# USBFS0_1.0 register map
Vendor: Texas Instruments
Peripheral module from a debugger description file (folder mspm0g511x).
Registers are 8-bit, read-write, no defined reset value unless marked. A register's access mark holds for its fields unless they carry their own. Offsets are as the file gives them; lines under a group give offsets from that group; [hi:lo] are bit positions; {n}, {i} and the like mark numbered series; 'fields as' and 'values as' point back to an identical list; <NAME> marks a mode.

## USBFS0 (part 1 of 2)
0x800 USBFS0_GPRCM group
  0x00 USBFS0_PWREN 32-bit — Power enable
    [0] ENABLE — Enable the power
      0=DISABLE (Disable Power); 1=ENABLE (Enable Power)
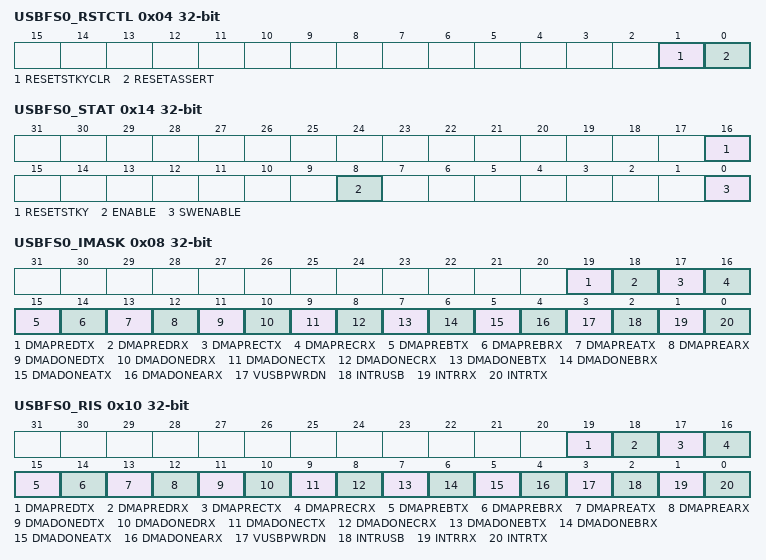
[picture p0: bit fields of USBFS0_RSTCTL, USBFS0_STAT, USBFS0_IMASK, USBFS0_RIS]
  0x04 USBFS0_RSTCTL 32-bit — Reset Control
    [1] RESETSTKYCLR — Clear the RESETSTKY bit in the STAT register
      0=NOP (Writing 0 has no effect); 1=CLR (Clear reset sticky bit)
    [0] RESETASSERT — Assert reset to the peripheral
      0=NOP (Writing 0 has no effect); 1=ASSERT (Assert reset)
  0x14 USBFS0_STAT 32-bit access per field — Status Register
    [16] RESETSTKY ro — This bit indicates, if the peripheral was reset, since this bit was cleared by RESETSTKYCLR in the RSTCTL register
      0=NORES (The peripheral has not been reset since this bit was last cleared by RESETSTKYCLR in the RSTCTL register); 1=RESET (The peripheral was reset since the last bit clear)
    [8] ENABLE rw — Peripheral enable status
      0=OFF (Peripheral is disabled); 1=ON (Peripheral is enabled)
    [0] SWENABLE ro — Software enable status. Shows if enabled via PWREN.ENABLE bit
      0=DISABLED (Not enabled via PWREN.ENABLE bit); 1=ENABLED (Enabled via PWREN.ENABLE bit)
0x1020 USBFS0_CPU_INT group
  0x00 USBFS0_IIDX 32-bit ro — Interrupt index
    [7:0] STAT — Interrupt index status
      0=NO_INTR (No bit is set means there is no pending interrupt request); 1=INTRTX (Endpoint 0 and the TX Endpoints interrupt); 2=INTRRX (RX Endpoints interrupt); 3=INTRUSB (USB Interrupts); 4=VUSBPWRDN (VUSB power down); 5=DMADONEARX (DMA-Done interrupt for Trigger USB-A-RX); 6=DMADONEATX (DMA-Done interrupt for Trigger USB-A-TX); 7=DMADONEBRX (DMA-Done interrupt for Trigger USB-B-RX); 8=DMADONEBTX (DMA-Done interrupt for Trigger USB-B-TX); 9=DMADONECRX (DMA-Done interrupt for Trigger USB-C-RX); 10=DMADONECTX (DMA-Done interrupt for Trigger USB-C-TX); 11=DMADONEDRX (DMA-Done interrupt for Trigger USB-D-RX); 12=DMADONEDTX (DMA-Done interrupt for Trigger USB-D-TX); 13=DMAPREARX (DMA-Pre interrupt for Trigger USB-A-RX); 14=DMAPREATX (DMA-Pre interrupt for Trigger USB-A-TX); 15=DMAPREBRX (DMA-Pre interrupt for Trigger USB-B-RX); 16=DMAPREBTX (DMA-Pre interrupt for Trigger USB-B-TX); 17=DMAPRECRX (DMA-Pre interrupt for Trigger USB-C-RX); 18=DMAPRECTX (DMA-Pre interrupt for Trigger USB-C-TX); 19=DMAPREDRX (DMA-Pre interrupt for Trigger USB-D-RX); 20=DMAPREDTX (DMA-Pre interrupt for Trigger USB-D-TX)
  0x08 USBFS0_IMASK 32-bit — Interrupt mask
    [all] fields
      0=CLR (Interrupt Disabled.); 1=SET (Interrupt Enabled.)
    [19] DMAPREDTX — DMA-Pre interrupt for Trigger USB-D-TX
    [18] DMAPREDRX — DMA-Pre interrupt for Trigger USB-D-RX
    [17] DMAPRECTX — DMA-Pre interrupt for Trigger USB-C-TX
    [16] DMAPRECRX — DMA-Pre interrupt for Trigger USB-C-RX
    [15] DMAPREBTX — DMA-Pre interrupt for Trigger USB-B-TX
    [14] DMAPREBRX — DMA-Pre interrupt for Trigger USB-B-RX
    [13] DMAPREATX — DMA-Pre interrupt for Trigger USB-A-TX
    [12] DMAPREARX — DMA-Pre interrupt for Trigger USB-A-RX
    [11] DMADONEDTX — DMA-Done interrupt for Trigger USB-D-TX
    [10] DMADONEDRX — DMA-Done interrupt for Trigger USB-D-RX
    [9] DMADONECTX — DMA-Done interrupt for Trigger USB-C-TX
    [8] DMADONECRX — DMA-Done interrupt for Trigger USB-C-RX
    [7] DMADONEBTX — DMA-Done interrupt for Trigger USB-B-TX
    [6] DMADONEBRX — DMA-Done interrupt for Trigger USB-B-RX
    [5] DMADONEATX — DMA-Done interrupt for Trigger USB-A-TX
    [4] DMADONEARX — DMA-Done interrupt for Trigger USB-A-RX
    [3] VUSBPWRDN — VUSB Power Down
    [2] INTRUSB — USB Interrupts
    [1] INTRRX — RX Endpoints interrupt
    [0] INTRTX — Endpoint 0 and the TX Endpoints interrupt
  0x10 USBFS0_RIS 32-bit — Raw interrupt status
    [all] fields
      0=CLR (Interrupt did not occur); 1=SET (Interrupt occured)
    [19] DMAPREDTX — DMA-Pre interrupt for Trigger USB-D-TX
    [18] DMAPREDRX — DMA-Pre interrupt for Trigger USB-D-RX
    [17] DMAPRECTX — DMA-Pre interrupt for Trigger USB-C-TX
    [16] DMAPRECRX — DMA-Pre interrupt for Trigger USB-C-RX
    [15] DMAPREBTX — DMA-Pre interrupt for Trigger USB-B-TX
    [14] DMAPREBRX — DMA-Pre interrupt for Trigger USB-B-RX
    [13] DMAPREATX — DMA-Pre interrupt for Trigger USB-A-TX
    [12] DMAPREARX — DMA-Pre interrupt for Trigger USB-A-RX
    [11] DMADONEDTX — DMA-Done interrupt for Trigger USB-D-TX
    [10] DMADONEDRX — DMA-Done interrupt for Trigger USB-D-RX
    [9] DMADONECTX — DMA-Done interrupt for Trigger USB-C-TX
    [8] DMADONECRX — DMA-Done interrupt for Trigger USB-C-RX
    [7] DMADONEBTX — DMA-Done interrupt for Trigger USB-B-TX
    [6] DMADONEBRX — DMA-Done interrupt for Trigger USB-B-RX
    [5] DMADONEATX — DMA-Done interrupt for Trigger USB-A-TX
    [4] DMADONEARX — DMA-Done interrupt for Trigger USB-A-RX
    [3] VUSBPWRDN — VUSB Power Down
    [2] INTRUSB — USB Interrupts
    [1] INTRRX — RX Endpoints interrupt
    [0] INTRTX — Endpoint 0 and the TX Endpoints interrupt
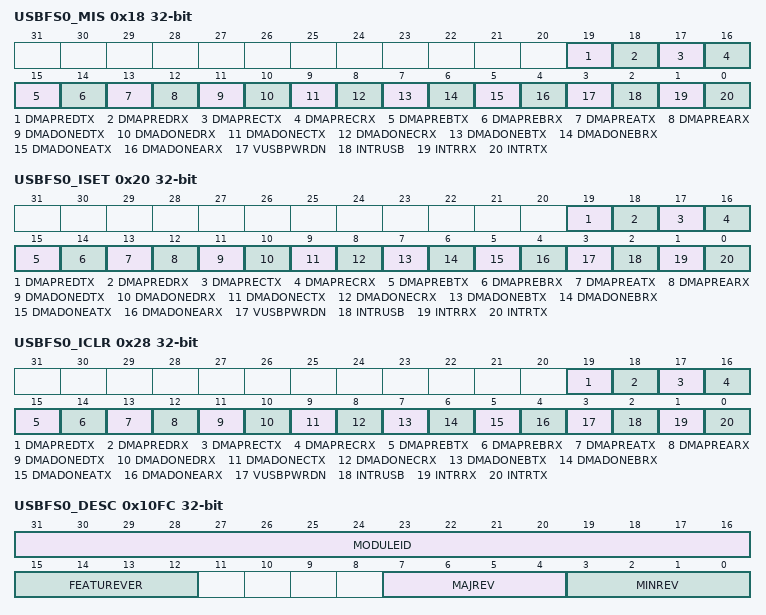
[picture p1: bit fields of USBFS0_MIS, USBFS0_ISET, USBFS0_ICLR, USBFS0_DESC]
  0x18 USBFS0_MIS 32-bit — Masked interrupt status
    fields as USBFS0_CPU_INT.USBFS0_RIS
  0x20 USBFS0_ISET 32-bit — Interrupt set
    [all] fields
      0=NO_EFFECT (Writing 0 has No Effect); 1=SET (Write 1 to set the interrupt)
    [19] DMAPREDTX — DMA-Pre interrupt for Trigger USB-D-TX
    [18] DMAPREDRX — DMA-Pre interrupt for Trigger USB-D-RX
    [17] DMAPRECTX — DMA-Pre interrupt for Trigger USB-C-TX
    [16] DMAPRECRX — DMA-Pre interrupt for Trigger USB-C-RX
    [15] DMAPREBTX — DMA-Pre interrupt for Trigger USB-B-TX
    [14] DMAPREBRX — DMA-Pre interrupt for Trigger USB-B-RX
    [13] DMAPREATX — DMA-Pre interrupt for Trigger USB-A-TX
    [12] DMAPREARX — DMA-Pre interrupt for Trigger USB-A-RX
    [11] DMADONEDTX — DMA-Done interrupt for Trigger USB-D-TX
    [10] DMADONEDRX — DMA-Done interrupt for Trigger USB-D-RX
    [9] DMADONECTX — DMA-Done interrupt for Trigger USB-C-TX
    [8] DMADONECRX — DMA-Done interrupt for Trigger USB-C-RX
    [7] DMADONEBTX — DMA-Done interrupt for Trigger USB-B-TX
    [6] DMADONEBRX — DMA-Done interrupt for Trigger USB-B-RX
    [5] DMADONEATX — DMA-Done interrupt for Trigger USB-A-TX
    [4] DMADONEARX — DMA-Done interrupt for Trigger USB-A-RX
    [3] VUSBPWRDN — VUSB Power Down
    [2] INTRUSB — USB Interrupts
    [1] INTRRX — RX Endpoints interrupt
    [0] INTRTX — Endpoint 0 and the TX Endpoints interrupt
  0x28 USBFS0_ICLR 32-bit — Interrupt clear
    [all] fields
      0=NO_EFFECT (Writing 0 has No Effect); 1=CLR (Write 1 to clear the interrupt)
    [19] DMAPREDTX — DMA-Pre interrupt for Trigger USB-D-TX
    [18] DMAPREDRX — DMA-Pre interrupt for Trigger USB-D-RX
    [17] DMAPRECTX — DMA-Pre interrupt for Trigger USB-C-TX
    [16] DMAPRECRX — DMA-Pre interrupt for Trigger USB-C-RX
    [15] DMAPREBTX — DMA-Pre interrupt for Trigger USB-B-TX
    [14] DMAPREBRX — DMA-Pre interrupt for Trigger USB-B-RX
    [13] DMAPREATX — DMA-Pre interrupt for Trigger USB-A-TX
    [12] DMAPREARX — DMA-Pre interrupt for Trigger USB-A-RX
    [11] DMADONEDTX — DMA-Done interrupt for Trigger USB-D-TX
    [10] DMADONEDRX — DMA-Done interrupt for Trigger USB-D-RX
    [9] DMADONECTX — DMA-Done interrupt for Trigger USB-C-TX
    [8] DMADONECRX — DMA-Done interrupt for Trigger USB-C-RX
    [7] DMADONEBTX — DMA-Done interrupt for Trigger USB-B-TX
    [6] DMADONEBRX — DMA-Done interrupt for Trigger USB-B-RX
    [5] DMADONEATX — DMA-Done interrupt for Trigger USB-A-TX
    [4] DMADONEARX — DMA-Done interrupt for Trigger USB-A-RX
    [3] VUSBPWRDN — VUSB Power Down
    [2] INTRUSB — USB Interrupts
    [1] INTRRX — RX Endpoints interrupt
    [0] INTRTX — Endpoint 0 and the TX Endpoints interrupt
0x10E0 USBFS0_EVT_MODE 32-bit ro — Event Mode
  [1:0] EVT0_CFG — Event line mode select for event corresponding to (IPSTANDARD.INT_EVENT)(0)
    0=DISABLE (The interrupt or event line is disabled.); 1=SOFTWARE (The interrupt or event line is in software mode. Software must clear the RIS.); 2=HARDWARE (The interrupt or event line is in hardware mode. The hardware (another module) clears automatically the associated RIS flag.)
0x10FC USBFS0_DESC 32-bit — Module Description
  [31:16] MODULEID — Module identification contains a unique peripheral identification number. The assignments are maintained in a central database for all of the platform modules to ensure uniqueness.
    0=MINIMUM (Smallest value); 0xFFFF=MAXIMUM (Highest possible value)
  [15:12] FEATUREVER — Feature Set for the module *instance*
    0=MINIMUM (Smallest value); 15=MAXIMUM (Highest possible value)
  [7:4] MAJREV — Major rev of the IP
    values as FEATUREVER
  [3:0] MINREV — Minor rev of the IP
    values as FEATUREVER
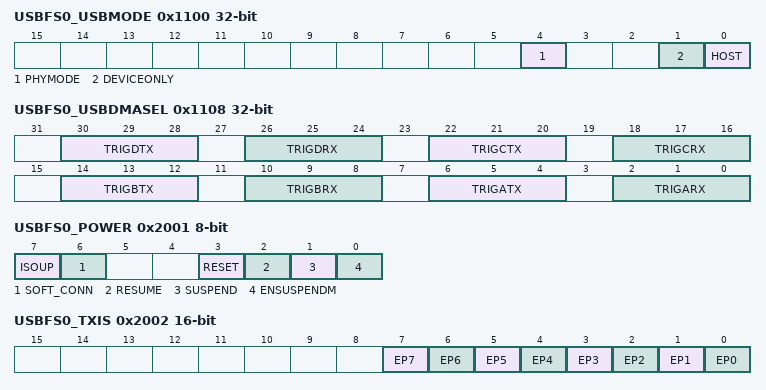
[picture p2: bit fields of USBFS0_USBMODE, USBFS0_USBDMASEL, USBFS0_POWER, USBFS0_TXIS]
0x1100 USBFS0_USBMODE 32-bit — USB mode control
  [4] PHYMODE — USB PHY mode. Defines whether DP/DM pins are controled by USB module or IOMUX/GPIO module.
    0=GPIO (The DP/DM pins are assighed to IOMUX/GPIO module,); 1=USB (The DP/DM pins are assighed to USB module.)
  [1] DEVICEONLY — USB is configured as DEVICE_ONLY mode
    0=DISABLE (USB is configured as DEVICE or HOST.); 1=ENABLE (USB is configured as DEVICE only mode.)
  [0] HOST — USB is configured as HOST mode
    0=DISABLE (USB is configured as DEVICE or HOST.); 1=ENABLE (USB is configured as HOST)
0x1104 USBFS0_USBMONITOR 32-bit — USB Clock Control Register
  [0] VUSBEN — Enable the 1/3 resistor divider for VUSB supply. Set this bit to monitor the VUSB supply with the ADC.
    0=DISABLE (VUSB monitor disabled); 1=ENABLE (VUSB monitor enabled)
0x1108 USBFS0_USBDMASEL 32-bit — USB DMA trigger select
  [all] fields
    0=DIS (Disabled); {v}=EP{v} (Endpoint {v}) (v=1..7)
  [30:28] TRIGDTX — TRIG D TX select specifies the TX mapping of the USB endpoint on DMA trigger USB-D-TX
  [26:24] TRIGDRX — TRIG D RX select specifies the RX mapping of the USB endpoint on DMA trigger USB-D-RX
  [22:20] TRIGCTX — TRIG C TX select specifies the TX mapping of the USB endpoint on DMA trigger USB-C-TX
  [18:16] TRIGCRX — TRIG C RX select specifies the RX mapping of the USB endpoint on DMA trigger USB-C-RX
  [14:12] TRIGBTX — TRIG B TX select specifies the TX mapping of the USB endpoint on DMA trigger USB-B-TX
  [10:8] TRIGBRX — TRIG B RX select specifies the RX mapping of the USB endpoint on DMA trigger USB-B-RX
  [6:4] TRIGATX — TRIG A TX select specifies the TX mapping of the USB endpoint on DMA trigger USB-A-TX
  [2:0] TRIGARX — TRIG A RX select specifies the RX mapping of the USB endpoint on DMA trigger USB-A-RX
0x2000 USBFS0_FADDR — USB Device Functional Address
  [6:0] FUNCADDR — FAddr is an 8-bit register that should be written with the 7-bit address of the peripheral part of the transaction. When the USB module is being used in Peripheral mode (DevCtl.D2=0), this register should be written with the address received through a SET_ADDRESS command, which will then be used for decoding the function address in subsequent token packets. Notes: Peripheral Mode Only!!
0x2001 USBFS0_POWER — USB Power Control
  [7] ISOUP — Isochronous Update. When set by the CPU, the USB module will wait for an SOF token from the time TXRDY bit is set in the USBTXCSRLn before sending the packet. If an IN token is received before an SOF token, then a zero length data packet will be sent. Note: Only valid in Peripheral Mode. Also, this bit only affects endpoints performing Isochronous transfers.
    0=NO_EFFECT; 1=WAIT_SOF (The USB controller waits for an SOF token.)
  [6] SOFT_CONN — Soft Connect/Disconnect feature. The USB D+/D- lines are enabled when this bit is set by the CPU and tri-stated when this bit is cleared by the CPU. Note: Only valid in Peripheral Mode.
    0=TRISTATE (The USB D+/D- lines are tri-stated.); 1=ENABLE (The USB D+/D- lines are enabled.)
  [3] RESET — This bit is set when Reset signaling is present on the bus. Note: This bit is Read/Write from the CPU in Host Mode but Read-Only in Peripheral Mode.
    0=DISABLE (Ends RESET signaling on the bus.); 1=ENABLE (Enables RESET signaling on the bus.)
  [2] RESUME — Set by the CPU to generate Resume signaling when the device is in Suspend mode. In Peripheral mode, the CPU should clear this bit after 10 ms (a maximum of 15 ms), to end Resume signaling. In Host mode, the CPU should clear this bit after 20 ms.
    0=DISABLE (Ends RESUME signaling on the bus.); 1=ENABLE (Enables RESUME signaling when the Device is in SUSPEND mode.)
  [1] SUSPEND — In Host mode, this bit is set by the CPU to enter Suspend mode. In Peripheral mode, this bit is set on entry into Suspend mode. It is cleared when the CPU reads the interrupt register, or sets the Resume bit.
    0=DISABLE (Ends SUSPEND signaling); 1=ENABLE (Enables SUSPEND signaling)
  [0] ENSUSPENDM — Set by the CPU to enable the Suspend mode for the USB PHY.
    0=DISABLE (USB PHY is powered); 1=ENABLE (Powers down the internal USB PHY.)
0x2002 USBFS0_TXIS 16-bit ro — USB Transmit Interrupt Status
  [n] EP{n} (n=1..7) — Transmit Endpoint {n} Interrupt
    0=NO_INT (No interrupt); 1=INT (The Endpoint {n} transmit interrupt is asserted.)
  [0] EP0 — Transmit Endpoint 0 Interrupt
    0=NO_INT (No interrupt); 1=INT (The Endpoint 0 transmit and receive interrupt is asserted.)
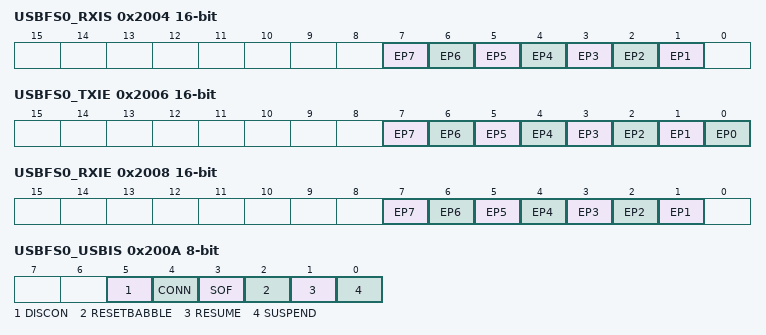
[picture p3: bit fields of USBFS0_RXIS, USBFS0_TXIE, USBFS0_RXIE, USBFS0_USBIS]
0x2004 USBFS0_RXIS 16-bit ro — USB Receive Interrupt Status
  [n] EP{n} (n=1..7) — Recieve Endpoint {n} Interrupt
    values as USBFS0_TXIS.EP1
0x2006 USBFS0_TXIE 16-bit — USB Transmit Interrupt Enable
  [n] EP{n} (n=1..7) — Transmit Endpoint {n} Interrupt Enable
    0=DISABLE (The EP{n} transmit interrupt is suppressed and not sent to the interrupt controller.); 1=ENABLE (An interrupt is sent to the interrupt controller when the EP{n} bit in the USBTXIS register is set.)
  [0] EP0 — Transmit Endpoint 0 Interrupt Enable
    0=DISABLE (The EP0 transmit and receive interrupt is suppressed and not sent to the interupt controller.); 1=ENABLE (An interrupt is sent to the interrupt controller when the EP0 bit in the USBTXIS register is set.)
0x2008 USBFS0_RXIE 16-bit — USB Receive Interrupt Enable
  [n] EP{n} (n=1..7) — Recieve Endpoint {n} Interrupt Enable
    values as USBFS0_TXIS.EP1
0x200A USBFS0_USBIS ro — USB General Interrupt Status
  [5] DISCON — Set in Host mode when a device disconnect is detected. Set in Peripheral mode when a session ends. Valid at all transaction speeds.
    0=NO_INT (No interrupt); 1=INT (The device has been disconnected from the host.)
  [4] CONN — Set when a device connection is detected. Note: Only valid in Host mode. Valid at all transaction speeds.
    0=NO_INT (No interrupt); 1=INT (The device has detected a connection to the host.)
  [3] SOF — Start of frame
    0=NO_INT (No interrupt); 1=INT (A new frame has started.)
  [2] RESETBABBLE — Device mode - RESET: Set in Peripheral mode when Reset signaling is detected on the bus. Host mode - BABBLE: Set in Host mode when babble is detected. Note: Only active after first SOF has been sent.
    0=NO_INT (No interrupt); 1=INT (RESET / BABBLE signaling has been detected on the bus.)
  [1] RESUME — Set when Resume signaling is detected on the bus while the USB controller is in Suspend mode.
    0=NO_INT (No interrupt); 1=INT (RESUME signaling has been detected on the bus.)
  [0] SUSPEND — Set when Suspend signaling is detected on the bus. Note: Only valid in Peripheral mode.
    0=NO_INT (No interrupt); 1=INT (SUSPEND signaling has been detected on the bus.)
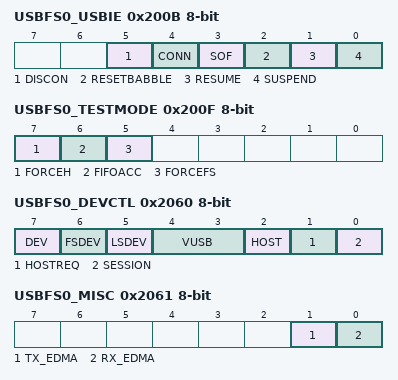
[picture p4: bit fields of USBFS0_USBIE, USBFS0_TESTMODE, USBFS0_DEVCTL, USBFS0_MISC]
0x200B USBFS0_USBIE access per field — USB General Interrupt Enable
  [5] DISCON rw — Interrupt enable for session disconnect.
    0=DISABLE (The DISCON interrupt is suppressed and not sent to the interrupt controller.); 1=ENABLE (An interrupt is sent to the interrupt controller when the DISCON bit in the USBIS register is set.)
  [4] CONN rw — Interrupt enable for connect detected. Note: Only valid in Host mode. Valid at all transaction speeds.
    0=DISABLE (The CONN interrupt is suppressed and not sent to the interrupt controller.); 1=ENABLE (An interrupt is sent to the interrupt controller when the CONN bit in the USBIS register is set.)
  [3] SOF rw — Interrupt enable for Start of frame.
    0=DISABLE (The SOF interrupt is suppressed and not sent to the interrupt controller.); 1=ENABLE (An interrupt is sent to the interrupt controller when the SOF bit in the USBIS register is set.)
  [2] RESETBABBLE rw — Interrupt enable for RESET/BABBLE signaling detected.
    0=DSIABLE (The RESET interrupt is suppressed and not sent to the interrupt controller.); 1=ENABLE (An interrupt is sent to the interrupt controller when the RESET bit in the USBIS register is set.)
  [1] RESUME rw — Interrupt enable for RESUME signaling detected.
    0=DISABLE (The RESUME interrupt is suppressed and not sent to the interrupt controller.); 1=ENABLE (An interrupt is sent to the interrupt controller when the RESUME bit in the USBIS register is set.)
  [0] SUSPEND ro — Interrupt enable for SUSPEND signaling detected. Note: Only valid in Peripheral mode.
    0=DISABLE (The SUSPEND interrupt is suppressed and not sent to the interrupt controller.); 1=ENABLE (An interrupt is sent to the interrupt controller when the DISCON bit in the USBIS register is set.)
0x200C USBFS0_FRAME 16-bit ro — USB Last Received Frame Number
  [10:0] FRAME — Frame Number
0x200E USBFS0_EPINDEX — USB Endpoint Index
  [3:0] EPIDX — Endpoint Index. #br#This bit field configures which endpoint is accessed when reading or writing to one of the USB controller's indexed registers. A value of 0x0 corresponds to Endpoint 0 and a value of 0xF corresponds to Endpoint 15.
    {v}=EP{v} (Select EP{v} as indexed register) (v=0..7)
0x200F USBFS0_TESTMODE — USB Test Mode
  [7] FORCEH — Force Host Mode. The CPU sets this bit to instruct the core to enter Host mode when the Session bit is set, regardless of whether it is connected to any peripheral. The state of the CID input, HostDisconnect and LineState signals are ignored. The core will then remain in Host mode until the Session bit is cleared, even if a device is disconnected, and if the Force_Host bit remains set, will re-enter Host mode the next time the Session bit is set. While in this mode, status of the bus connection may be read using the DEV bit of the USBDEVCTL register. The operating speed is determined from the FORCEFS bit.
    0=NO_EFFECT; 1=EFFECT (Forces the USB controller to enter Host mode when the SESSION bit is set, regardless ofwhether the USB controller is connected to any peripheral. The state of the USB0DP and USB0DM signals is ignored. The USB controller then remains in Host mode until the SESSION #br#bit is cleared, even if a Device is disconnected. If the FORCEH bit remains set, the USB controller re-enters Host mode the next time the SESSION bit is set.)
  [6] FIFOACC — FIFO Access. The CPU sets this bit to transfer the packet in the Endpoint 0 TX FIFO to the Endpoint 0 Rx FIFO. Note: It is cleared automatically.
    0=NO_EFFECT; 1=EFFECT (Transfers the packet in the endpoint 0 transmit FIFO to the endpoint 0 receive FIFO.)
  [5] FORCEFS — Force Full Speed Upon Reset. The CPU sets this bit either in conjunction with bit 7 (FORCEH) or to force the USB controller into Full-speed mode when it receives a USB reset.
    0=LOW (The USB controller operates at Low Speed.); 1=FULL (Forces the USB controller into Full-Speed mode upon receiving a USB RESET.)
0x2010 USBFS0_IDXTXMAXP 16-bit access not given — Indexed TXMAP
0x2012 USBFS0_IDXTXCSRL access not given — Indexed TXCSRL
0x2013 USBFS0_IDXTXCSRH access not given — Indexed TXCSRH
0x2014 USBFS0_IDXRXMAXP 16-bit access not given — Indexed RXMAXP
0x2016 USBFS0_IDXRXCSRL access not given — Indexed RXCSRL
0x2017 USBFS0_IDXRXCSRH access not given — Indexed RXCSRH
0x2018 USBFS0_IDXRXCOUNT 16-bit access not given — Indexed RXCOUNT
0x201A USBFS0_IDXTXTYPE access not given — Indexed TXTYPE
0x201B USBFS0_IDXTXINTERVAL access not given — Indexed TXINTERVAL
0x201C USBFS0_IDXRXTYPE access not given — Indexed RXTYPE
0x201D USBFS0_IDXRXINTERVAL access not given — Indexed RXINTERVAL
0x201F USBFS0_IDXFIFOSZ access not given — Indexed FIFOSZ
{0x2020+4i} USBFS0_FIFO[{i}] (i=0..15) 32-bit access not given — USB FIFO Endpoint [n]
0x2060 USBFS0_DEVCTL access per field — USB Device Control
  [7] DEV ro — Device Mode. This Read-only bit indicates whether the USB controller is operating as the host mode or device mode. Note: Only valid while a session is in progress.
    0=HOST (The USB controller is operating in host mode.); 1=DEVICE (The USB controller is operating in device mode.)
  [6] FSDEV ro — Full Speed Device Detected. This Read-only bit is set when a full-speed device has been detected being connected to the port. Note: Only valid in Host mode.
    0=NO_DETCT (A full-speed Device has not been detected on the port.); 1=DETCT (A full-speed Device has been detected on the port.)
  [5] LSDEV ro — Low Speed Device Detected. This Read-only bit is set when a low-speed device has been detected being connected to the port. Note: Only valid in Host mode.
    0=NO_DETCT (A low-speed Device has not been detected on the port.); 1=DETCT (A low-speed Device has been detected on the port.)
  [4:3] VUSB ro — VUSB / USB-PHY is powered.
    0=NOT_POWERED (VUSB / USB-PHY supply is detected as under 1.35V.); 3=POWERED (VUSB / USB-PHY supply is detected as above 1.35V.)
  [2] HOST ro — Host Mode. This Read-only bit is set when the USB controller is acting as a Host. Note: Only valid while a session is in progress.
    0=DEVICE (The USB controller is acting as a Device.); 1=HOST (The USB controller is acting as a Host.)
  [1] HOSTREQ rw — When set, the USB controller will initiate the Host Negotiation when Suspend mode is entered. It is cleared when Host Negotiation is completed.
    0=NO_EFFECT; 1=EFFECT (Initiates the Host Negotiation when SUSPENDmode is entered.)
  [0] SESSION rw — Session Start/End. Host mode: This bit is set or cleared by the CPU to start or end a session. Device mode: This bit is set/cleared by the USB controller when a session starts/ends. It is also set by the CPU to initiate the Session Request Protocol. When the USB controller is in Suspend mode, the bit may be cleared by the CPU to perform a software disconnect. Note: Clearing this bit when the core is not suspended will result in undefined behavior.
    0=CLEAR (When operating as a Host: #br#When cleared by software, this bit ends a session. #br# #br#When operating as a Device: #br#The USB controller has ended a session. When the USB controller is in SUSPEND mode, this bit may be cleared by software to perform a software disconnect.); 1=SET (When operating as a Host: #br#When set by software, this bit starts a session. #br# #br#When operating as a Device: #br#The USB controller has started a session. When set by software, the Session Request Protocol is initiated. #br# #br#Clearing this bit when the USB controller is not suspended results in undefined behavior.)
0x2061 USBFS0_MISC — USB Miscellaneous Register
  [1] TX_EDMA — Transmit early DMA mode.
    0=LATE (Late mode: DMA_REQ signal for all IN Endpoints will be de-asserted when MAXP bytes have been written to an endpoint. This is late mode.); 1=EARLY (Early mode: DMA_REQ signal for all IN Endpoints will be de-asserted when MAXP-8 bytes have been written to an endpoint. This is early mode.)
  [0] RX_EDMA — Receive early DMA mode.
    0=LATE (Late mode: DMA_REQ signal for all OUT Endpoints will be de-asserted when MAXP bytes have been read to an endpoint.); 1=EARLY (Early Mode: DMA_REQ signal for all OUT Endpoints will be de-asserted when MAXP-8 bytes have been read to an endpoint.)
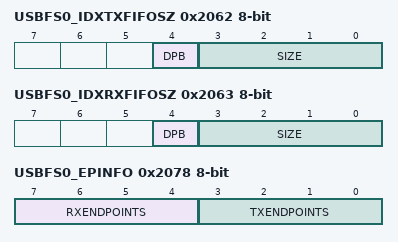
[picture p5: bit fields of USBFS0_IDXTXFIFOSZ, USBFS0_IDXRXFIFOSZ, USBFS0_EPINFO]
0x2062 USBFS0_IDXTXFIFOSZ — Indexed USB Transmit Dynamic FIFO Sizing
  [4] DPB — Double Packet Buffer Support
    0=SIGLE (Single packet buffering is supported.); 1=DOUBLE (Double packet buffering is enabled.)
  [3:0] SIZE — Max Packet Size
    0=BYTES_8 (FIFO size 8-byte); 1=BYTES_16 (FIFO size 16-byte); 2=BYTES_32 (FIFO size 32-byte); 3=BYTES_64 (FIFO size 64-byte); 4=BYTES_128 (FIFO size 128-byte); 5=BYTES_256 (FIFO size 256-byte); 6=BYTES_512 (FIFO size 512-byte); 7=BYTES_1024 (FIFO size 1024-byte); 8=BYTES_2048 (FIFO size 2048-byte)
0x2063 USBFS0_IDXRXFIFOSZ — Indexed USB Receive Dynamic FIFO Sizing
  [4] DPB — Double Packet Buffer Support
    values as USBFS0_IDXTXFIFOSZ.DPB
  [3:0] SIZE — Maximum packet size to be allowed. If DPB = 0, the FIFO also is this size; if DPB = 1, the FIFO is twice this size. Packet size in bytes:
    values as USBFS0_IDXTXFIFOSZ.SIZE
0x2064 USBFS0_IDXTXFIFOADD 16-bit — Indexed USB Transmit FIFO Start Address
  [13:0] ADDR — Endpoint Data
    0=0.0; 1=8.0; 2=16.0; 3=24.0; 4=32.0; 5=40.0; 6=48.0; 7=56.0; 8=64.0; 9=72.0; 10=80.0; 11=88.0; 12=96.0; 13=104.0; 14=112.0; 15=120.0; 16=128.0; 17=136.0; 18=144.0; 19=152.0; 20=160.0; 21=168.0; 22=176.0; 23=184.0; 24=192.0; 25=200.0; 26=208.0; 27=216.0; 28=224.0; 29=232.0; 30=240.0; 31=248.0; 32=256.0; 33=264.0; 34=272.0; 35=280.0; 36=288.0; 37=296.0; 38=304.0; 39=312.0; 40=320.0; 41=328.0; 42=336.0; 43=344.0; 44=352.0; 45=360.0; 46=368.0; 47=376.0; 48=384.0; 49=392.0; 50=400.0; 51=408.0; 52=416.0; 53=424.0; 54=432.0; 55=440.0; 56=448.0; 57=456.0; 58=464.0; 59=472.0; 60=480.0; 61=488.0; 62=496.0; 63=504.0; 64=512.0; 65=520.0; 66=528.0; 67=536.0; 68=544.0; 69=552.0; 70=560.0; 71=568.0; 72=576.0; 73=584.0; 74=592.0; 75=600.0; 76=608.0; 77=616.0; 78=624.0; 79=632.0; 80=640.0; 81=648.0; 82=656.0; 83=664.0; 84=672.0; 85=680.0; 86=688.0; 87=696.0; 88=704.0; 89=712.0; 90=720.0; 91=728.0; 92=736.0; 93=744.0; 94=752.0; 95=760.0; 96=768.0; 97=776.0; 98=784.0; 99=792.0; 100=800.0; 101=808.0; 102=816.0; 103=824.0; 104=832.0; 105=840.0; 106=848.0; 107=856.0; 108=864.0; 109=872.0; 110=880.0; 111=888.0; 112=896.0; 113=904.0; 114=912.0; 115=920.0; 116=928.0; 117=936.0; 118=944.0; 119=952.0; 120=960.0; 121=968.0; 122=976.0; 123=984.0; 124=992.0; 125=1000.0; 126=1008.0; 127=1016.0; 128=1024.0; 129=1032.0; 130=1040.0; 131=1048.0; 132=1056.0; 133=1064.0; 134=1072.0; 135=1080.0; 136=1088.0; 137=1096.0; 138=1104.0; 139=1112.0; 140=1120.0; 141=1128.0; 142=1136.0; 143=1144.0; 144=1152.0; 145=1160.0; 146=1168.0; 147=1176.0; 148=1184.0; 149=1192.0; 150=1200.0; 151=1208.0; 152=1216.0; 153=1224.0; 154=1232.0; 155=1240.0; 156=1248.0; 157=1256.0; 158=1264.0; 159=1272.0; 160=1280.0; 161=1288.0; 162=1296.0; 163=1304.0; 164=1312.0; 165=1320.0; 166=1328.0; 167=1336.0; 168=1344.0; 169=1352.0; 170=1360.0; 171=1368.0; 172=1376.0; 173=1384.0; 174=1392.0; 175=1400.0; 176=1408.0; 177=1416.0; 178=1424.0; 179=1432.0; 180=1440.0; 181=1448.0; 182=1456.0; 183=1464.0; 184=1472.0; 185=1480.0; 186=1488.0; 187=1496.0; 188=1504.0; 189=1512.0; 190=1520.0; 191=1528.0; 192=1536.0; 193=1544.0; 194=1552.0; 195=1560.0; 196=1568.0; 197=1576.0; 198=1584.0; 199=1592.0; 200=1600.0; 201=1608.0; 202=1616.0; 203=1624.0; 204=1632.0; 205=1640.0; 206=1648.0; 207=1656.0; 208=1664.0; 209=1672.0; 210=1680.0; 211=1688.0; 212=1696.0; 213=1704.0; 214=1712.0; 215=1720.0; 216=1728.0; 217=1736.0; 218=1744.0; 219=1752.0; 220=1760.0; 221=1768.0; 222=1776.0; 223=1784.0; 224=1792.0; 225=1800.0; 226=1808.0; 227=1816.0; 228=1824.0; 229=1832.0; 230=1840.0; 231=1848.0; 232=1856.0; 233=1864.0; 234=1872.0; 235=1880.0; 236=1888.0; 237=1896.0; 238=1904.0; 239=1912.0; 240=1920.0; 241=1928.0; 242=1936.0; 243=1944.0; 244=1952.0; 245=1960.0; 246=1968.0; 247=1976.0; 248=1984.0; 249=1992.0; 250=2000.0; 251=2008.0; 252=2016.0; 253=2024.0; 254=2032.0; 255=2040.0
0x2066 USBFS0_IDXRXFIFOADD 16-bit — Indexed USB Receive FIFO Start Address
  fields as USBFS0_IDXTXFIFOADD
0x2078 USBFS0_EPINFO ro — Endpoint Information
  [7:4] RXENDPOINTS — The number of Rx endpoints implemented in the design.
  [3:0] TXENDPOINTS — The number of TX endpoints implemented in the design.
0x2079 USBFS0_RAMINFO ro — USB FIFO Buffer RAM Information
  [3:0] RAMBITS — The width of the RAM address bus.
    8=RAM_1KB (USB FIFO RAM size is 1kB); 9=RAM_2KB (USB FIFO RAM size is 2kB); 10=RAM_4KB (USB FIFO RAM size is 4kB)
